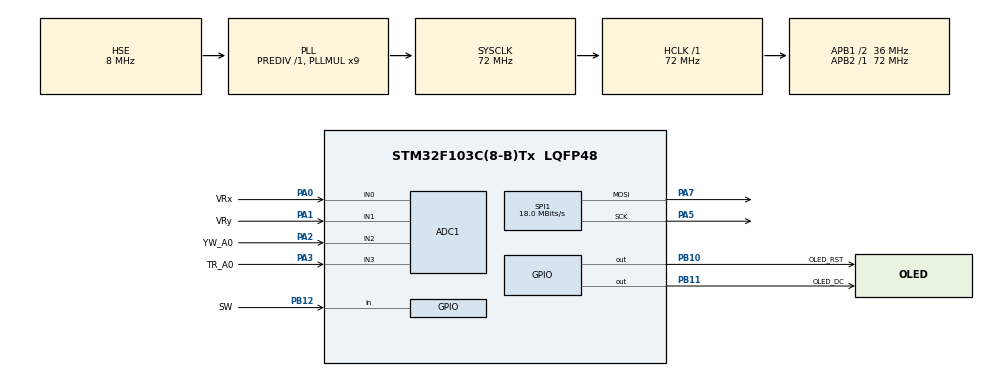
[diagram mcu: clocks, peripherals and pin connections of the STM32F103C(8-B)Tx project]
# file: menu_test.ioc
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ADC1.Channel-0\#ChannelRegularConversion=ADC_CHANNEL_0
ADC1.Channel-1\#ChannelRegularConversion=ADC_CHANNEL_1
ADC1.Channel-2\#ChannelRegularConversion=ADC_CHANNEL_2
ADC1.Channel-3\#ChannelRegularConversion=ADC_CHANNEL_3
ADC1.ContinuousConvMode=ENABLE
ADC1.NbrOfConversion=4
ADC1.NbrOfConversionFlag=1
ADC1.Rank-0\#ChannelRegularConversion=1
ADC1.Rank-1\#ChannelRegularConversion=2
ADC1.Rank-2\#ChannelRegularConversion=3
ADC1.Rank-3\#ChannelRegularConversion=4
ADC1.SamplingTime-0\#ChannelRegularConversion=ADC_SAMPLETIME_1CYCLE_5
ADC1.SamplingTime-1\#ChannelRegularConversion=ADC_SAMPLETIME_1CYCLE_5
ADC1.SamplingTime-2\#ChannelRegularConversion=ADC_SAMPLETIME_1CYCLE_5
ADC1.SamplingTime-3\#ChannelRegularConversion=ADC_SAMPLETIME_1CYCLE_5
ADC1.master=1
Dma.ADC1.0.Direction=DMA_PERIPH_TO_MEMORY
Dma.ADC1.0.Instance=DMA1_Channel1
Dma.ADC1.0.MemDataAlignment=DMA_MDATAALIGN_WORD
Dma.ADC1.0.MemInc=DMA_MINC_ENABLE
Dma.ADC1.0.Mode=DMA_CIRCULAR
Dma.ADC1.0.PeriphDataAlignment=DMA_PDATAALIGN_WORD
Dma.ADC1.0.PeriphInc=DMA_PINC_DISABLE
Dma.ADC1.0.Priority=DMA_PRIORITY_LOW
Dma.Request0=ADC1
Dma.Request1=SPI1_TX
Dma.SPI1_TX.1.Direction=DMA_MEMORY_TO_PERIPH
Dma.SPI1_TX.1.Instance=DMA1_Channel3
Dma.SPI1_TX.1.MemDataAlignment=DMA_MDATAALIGN_BYTE
Dma.SPI1_TX.1.MemInc=DMA_MINC_ENABLE
Dma.SPI1_TX.1.Mode=DMA_NORMAL
Dma.SPI1_TX.1.PeriphDataAlignment=DMA_PDATAALIGN_BYTE
Dma.SPI1_TX.1.PeriphInc=DMA_PINC_DISABLE
Dma.SPI1_TX.1.Priority=DMA_PRIORITY_LOW
Mcu.Family=STM32F1
Mcu.Name=STM32F103C(8-B)Tx
Mcu.Package=LQFP48
NVIC.DMA1_Channel3_IRQn=true\:0\:0\:false\:false\:true\:true\:true\:true
NVIC.PriorityGroup=NVIC_PRIORITYGROUP_4
NVIC.TIM3_IRQn=true\:0\:0\:false\:false\:true\:true\:true\:true
PA0-WKUP.GPIO_Label=VRx
PA0-WKUP.Signal=ADCx_IN0
PA1.GPIO_Label=VRy
PA1.Signal=ADCx_IN1
PA13.Mode=Serial_Wire
PA13.Signal=SYS_JTMS-SWDIO
PA14.Mode=Serial_Wire
PA14.Signal=SYS_JTCK-SWCLK
PA2.GPIO_Label=YW_A0
PA2.Signal=ADCx_IN2
PA3.GPIO_Label=TR_A0
PA3.Signal=ADCx_IN3
PA5.Mode=TX_Only_Simplex_Unidirect_Master
PA5.Signal=SPI1_SCK
PA7.Mode=TX_Only_Simplex_Unidirect_Master
PA7.Signal=SPI1_MOSI
PB10.GPIO_Label=OLED_RST
PB10.Signal=GPIO_Output
PB11.GPIO_Label=OLED_DC
PB11.Signal=GPIO_Output
PB12.GPIO_Label=SW
PB12.GPIO_PuPd=GPIO_PULLUP
PB12.Signal=GPIO_Input
PD0-OSC_IN.Mode=HSE-External-Oscillator
PD0-OSC_IN.Signal=RCC_OSC_IN
PD1-OSC_OUT.Mode=HSE-External-Oscillator
PD1-OSC_OUT.Signal=RCC_OSC_OUT
ProjectManager.HeapSize=0x200
ProjectManager.StackSize=0x400
ProjectManager.TargetToolchain=MDK-ARM V5.32
RCC.ADCPresc=RCC_ADCPCLK2_DIV6
RCC.AHBFreq_Value=72000000
RCC.APB1CLKDivider=RCC_HCLK_DIV2
RCC.APB1Freq_Value=36000000
RCC.APB1TimFreq_Value=72000000
RCC.APB2Freq_Value=72000000
RCC.APB2TimFreq_Value=72000000
RCC.EnbaleCSS=true
RCC.HCLKFreq_Value=72000000
RCC.PLLMUL=RCC_PLL_MUL9
RCC.PLLSourceVirtual=RCC_PLLSOURCE_HSE
RCC.SYSCLKFreq_VALUE=72000000
RCC.SYSCLKSource=RCC_SYSCLKSOURCE_PLLCLK
RCC.USBFreq_Value=72000000
SH.ADCx_IN0.0=ADC1_IN0,IN0
SH.ADCx_IN1.0=ADC1_IN1,IN1
SH.ADCx_IN2.0=ADC1_IN2,IN2
SH.ADCx_IN3.0=ADC1_IN3,IN3
SPI1.BaudRatePrescaler=SPI_BAUDRATEPRESCALER_4
SPI1.CalculateBaudRate=18.0 MBits/s
SPI1.Direction=SPI_DIRECTION_2LINES
SPI1.Mode=SPI_MODE_MASTER
SPI1.VirtualType=VM_MASTER
TIM3.Period=100-1
TIM3.Prescaler=720-1
VP_TIM3_VS_ClockSourceINT.Mode=Internal
board=custom

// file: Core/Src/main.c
/* USER CODE BEGIN Header */
/**
  ******************************************************************************
  * @file           : main.c
  * @brief          : Main program body
  ******************************************************************************
  * @attention
  *
  * Copyright (c) 2023 STMicroelectronics.
  * All rights reserved.
  *
  * This software is licensed under terms that can be found in the LICENSE file
  * in the root directory of this software component.
  * If no LICENSE file comes with this software, it is provided AS-IS.
  *
  ******************************************************************************
  */
/* USER CODE END Header */
#include "main.h"
#include "adc.h"
#include "dma.h"
#include "spi.h"
#include "tim.h"
#include "gpio.h"

/* USER CODE BEGIN Includes */
#include "menu.h"
/* USER CODE END Includes */

/* USER CODE BEGIN PV */
uint32_t ADCarray[4];
/* USER CODE END PV */

void SystemClock_Config(void);

int main(void)
{

  /* MCU Configuration--------------------------------------------------------*/

  /* Reset of all peripherals, Initializes the Flash interface and the Systick. */
  HAL_Init();

  /* Configure the system clock */
  SystemClock_Config();

  /* Initialize all configured peripherals */
  MX_GPIO_Init();
  MX_DMA_Init();
  MX_ADC1_Init();
  MX_SPI1_Init();
  MX_TIM3_Init();
  /* USER CODE BEGIN 2 */
	HAL_ADC_Start_DMA(&hadc1, ADCarray, 4);
	HAL_TIM_Base_Start_IT(&htim3);
	MenuInit();
  /* USER CODE END 2 */

  /* Infinite loop */
  while (1)
  {

    /* USER CODE BEGIN 3 */
		MenuRun();
  }
  /* USER CODE END 3 */
}

void SystemClock_Config(void)
{
  RCC_OscInitTypeDef RCC_OscInitStruct = {0};
  RCC_ClkInitTypeDef RCC_ClkInitStruct = {0};
  RCC_PeriphCLKInitTypeDef PeriphClkInit = {0};

  /** Initializes the RCC Oscillators according to the specified parameters
  * in the RCC_OscInitTypeDef structure.
  */
  RCC_OscInitStruct.OscillatorType = RCC_OSCILLATORTYPE_HSE;
  RCC_OscInitStruct.HSEState = RCC_HSE_ON;
  RCC_OscInitStruct.HSEPredivValue = RCC_HSE_PREDIV_DIV1;
  RCC_OscInitStruct.HSIState = RCC_HSI_ON;
  RCC_OscInitStruct.PLL.PLLState = RCC_PLL_ON;
  RCC_OscInitStruct.PLL.PLLSource = RCC_PLLSOURCE_HSE;
  RCC_OscInitStruct.PLL.PLLMUL = RCC_PLL_MUL9;
  if (HAL_RCC_OscConfig(&RCC_OscInitStruct) != HAL_OK)
  {
    Error_Handler();
  }

  /** Initializes the CPU, AHB and APB buses clocks
  */
  RCC_ClkInitStruct.ClockType = RCC_CLOCKTYPE_HCLK|RCC_CLOCKTYPE_SYSCLK
                              |RCC_CLOCKTYPE_PCLK1|RCC_CLOCKTYPE_PCLK2;
  RCC_ClkInitStruct.SYSCLKSource = RCC_SYSCLKSOURCE_PLLCLK;
  RCC_ClkInitStruct.AHBCLKDivider = RCC_SYSCLK_DIV1;
  RCC_ClkInitStruct.APB1CLKDivider = RCC_HCLK_DIV2;
  RCC_ClkInitStruct.APB2CLKDivider = RCC_HCLK_DIV1;

  if (HAL_RCC_ClockConfig(&RCC_ClkInitStruct, FLASH_LATENCY_2) != HAL_OK)
  {
    Error_Handler();
  }
  PeriphClkInit.PeriphClockSelection = RCC_PERIPHCLK_ADC;
  PeriphClkInit.AdcClockSelection = RCC_ADCPCLK2_DIV6;
  if (HAL_RCCEx_PeriphCLKConfig(&PeriphClkInit) != HAL_OK)
  {
    Error_Handler();
  }

  /** Enables the Clock Security System
  */
  HAL_RCC_EnableCSS();
}

void Error_Handler(void)
{
  __disable_irq();
  while (1)
  {
  }
}
